# CTRL_MMR0_CFG0 register map
Vendor: Texas Instruments
Registers are 32-bit, read-write, reset 0x0 unless marked. A register's access mark holds for its fields unless they carry their own. Offsets are as the file gives them; [hi:lo] are bit positions; {n}, {i} and the like mark numbered series.

## CTRL_MMR0_CFG0 (part 2 of 2)
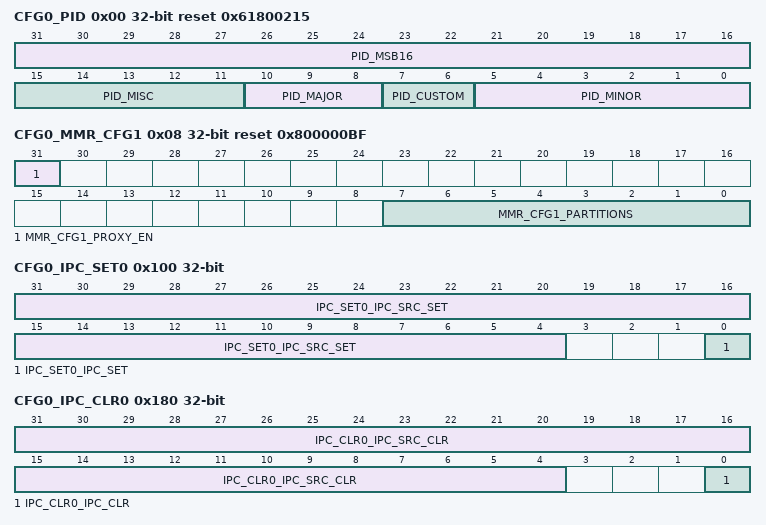
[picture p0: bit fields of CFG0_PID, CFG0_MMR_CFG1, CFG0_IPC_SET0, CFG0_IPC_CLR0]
0x00 CFG0_PID ro reset 0x61800215
  [31:16] PID_MSB16, [15:11] PID_MISC, [10:8] PID_MAJOR, [7:6] PID_CUSTOM, [5:0] PID_MINOR
0x08 CFG0_MMR_CFG1 ro reset 0x800000BF
  [31] MMR_CFG1_PROXY_EN — Proxy addressing activated
  [7:0] MMR_CFG1_PARTITIONS — Indicates present partitions
0x100 CFG0_IPC_SET0 access not given
  [31:4] IPC_SET0_IPC_SRC_SET — Read returns current value Write: 0 - No effect 1 - Sets both corresponding IPC_CLR and the IPC_SET bits (access R/W1TS)
  [0] IPC_SET0_IPC_SET — Read returns 0 Write: 0 - No effect 1 - Sets both corresponding IPC_CLR and the IPC_SET bits (access R/W1TS)
0x180 CFG0_IPC_CLR0 access not given
  [31:4] IPC_CLR0_IPC_SRC_CLR — Read returns current value Write: 0 - No effect 1 - Clears both corresponding IPC_CLR and the IPC_SET bits (access R/W1TC)
  [0] IPC_CLR0_IPC_CLR — Read returns current value Write: 0 - No effect 1 - Clears both corresponding IPC_CLR and the IPC_SET bits (access R/W1TC)
{0x1008+0x4000*i} CFG0_LOCK{i}_KICK0 (i=0..2)
  [31:0] LOCK{i}_KICK0 — - KICK0 component
{0x100C+0x4000*i} CFG0_LOCK{i}_KICK1 (i=0..2)
  [31:0] LOCK{i}_KICK1 — - KICK1 component
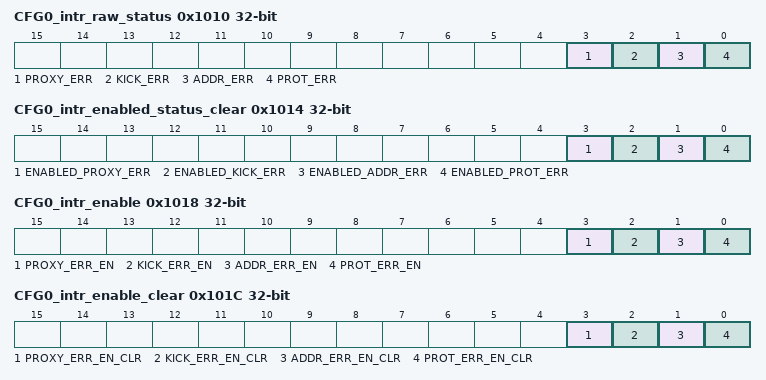
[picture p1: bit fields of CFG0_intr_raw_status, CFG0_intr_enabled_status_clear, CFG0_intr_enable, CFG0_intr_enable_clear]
0x1010 CFG0_intr_raw_status access not given
  [3] PROXY_ERR — Proxy0 access violation error. Raw status is read. Write a 1 to set the status. Writing a 0 has no effect. (access R/W1TS)
  [2] KICK_ERR — Kick access violation error. Raw status is read. Write a 1 to set the status. Writing a 0 has no effect. (access R/W1TS)
  [1] ADDR_ERR — Addressing violation error. Raw status is read. Write a 1 to set the status. Writing a 0 has no effect. (access R/W1TS)
  [0] PROT_ERR — Protection violation error. Raw status is read. Write a 1 to set the status. Writing a 0 has no effect. (access R/W1TS)
0x1014 CFG0_intr_enabled_status_clear access not given
  [3] ENABLED_PROXY_ERR — Proxy0 access violation error. Enabled status is read. Write a 1 to clear the status. Writing a 0 has no effect. (access R/W1TC)
  [2] ENABLED_KICK_ERR — Kick access violation error. Enabled status is read. Write a 1 to clear the status. Writing a 0 has no effect. (access R/W1TC)
  [1] ENABLED_ADDR_ERR — Addressing violation error. Enabled status is read. Write a 1 to clear the status. Writing a 0 has no effect. (access R/W1TC)
  [0] ENABLED_PROT_ERR — Protection violation error. Enabled status is read. Write a 1 to clear the status. Writing a 0 has no effect. (access R/W1TC)
0x1018 CFG0_intr_enable access not given
  [3] PROXY_ERR_EN — Proxy0 access violation error enable. Write a 1 to set the enable. Writing a 0 has no effect. (access R/W1TS)
  [2] KICK_ERR_EN — Kick access violation error enable. Write a 1 to set the enable. Writing a 0 has no effect. (access R/W1TS)
  [1] ADDR_ERR_EN — Addressing violation error enable. Write a 1 to set the enable. Writing a 0 has no effect. (access R/W1TS)
  [0] PROT_ERR_EN — Protection violation error enable. Write a 1 to set the enable. Writing a 0 has no effect. (access R/W1TS)
0x101C CFG0_intr_enable_clear access not given
  [3] PROXY_ERR_EN_CLR — Proxy0 access violation error enable clear. Write a 1 to clear the enable. Writing a 0 has no effect. (access R/W1TC)
  [2] KICK_ERR_EN_CLR — Kick access violation error enable clear. Write a 1 to clear the enable. Writing a 0 has no effect. (access R/W1TC)
  [1] ADDR_ERR_EN_CLR — Addressing violation error enable clear. Write a 1 to clear the enable. Writing a 0 has no effect. (access R/W1TC)
  [0] PROT_ERR_EN_CLR — Protection violation error enable clear. Write a 1 to clear the enable. Writing a 0 has no effect. (access R/W1TC)
0x1020 CFG0_eoi
  [7:0] EOI_VECTOR — EOI vector value. Write this with interrupt distribution value in the chip.
0x1024 CFG0_fault_address ro
  [31:0] FAULT_ADDR — Fault Address.
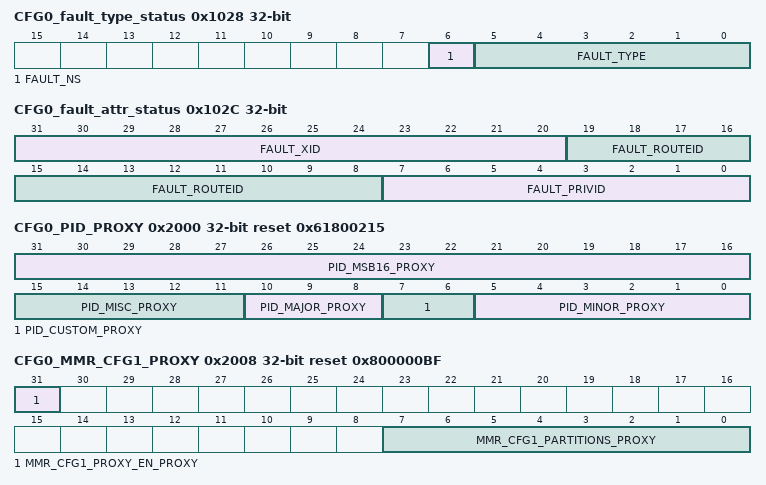
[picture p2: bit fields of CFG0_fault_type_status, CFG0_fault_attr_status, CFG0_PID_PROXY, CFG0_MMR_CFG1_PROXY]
0x1028 CFG0_fault_type_status ro
  [6] FAULT_NS — Non-secure access.
  [5:0] FAULT_TYPE — Fault Type 10_0000 = Supervisor read fault - priv = 1 dir = 1 dtype != 1 01_0000 = Supervisor write fault - priv = 1 dir = 0 00_1000 = Supervisor execute fault - priv = 1 dir = 1 dtype = 1 00_0100 = User read fault - priv = 0 dir = 1 dtype = 1 00_0010 = User write fault - priv = 0 dir = 0 00_0001 = User execute fault - priv = 0 dir = 1 dtype = 1 00_0000 = No fault
0x102C CFG0_fault_attr_status ro
  [31:20] FAULT_XID — XID.
  [19:8] FAULT_ROUTEID — Route ID.
  [7:0] FAULT_PRIVID — Privilege ID.
0x1030 CFG0_fault_clear wo
  [0] FAULT_CLR — Fault clear. Writing a 1 clears the current fault. Writing a 0 has no effect.
{0x1100+4i} CFG0_CLAIMREG_P0_R{i}_READONLY ro (i=0..6)
  [31:0] CLAIMREG_P0_R{i}_READONLY — Claim bits for Partition 0
0x2000 CFG0_PID_PROXY ro reset 0x61800215
  [31:16] PID_MSB16_PROXY, [15:11] PID_MISC_PROXY, [10:8] PID_MAJOR_PROXY, [7:6] PID_CUSTOM_PROXY, [5:0] PID_MINOR_PROXY
0x2008 CFG0_MMR_CFG1_PROXY ro reset 0x800000BF
  [31] MMR_CFG1_PROXY_EN_PROXY — Proxy addressing activated
  [7:0] MMR_CFG1_PARTITIONS_PROXY — Indicates present partitions
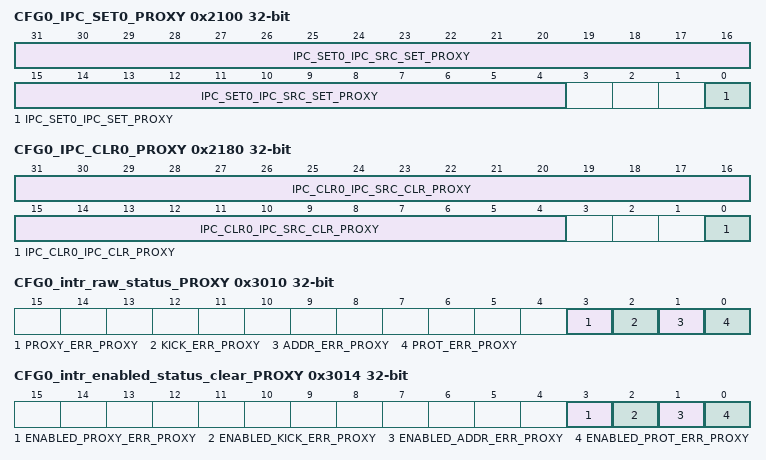
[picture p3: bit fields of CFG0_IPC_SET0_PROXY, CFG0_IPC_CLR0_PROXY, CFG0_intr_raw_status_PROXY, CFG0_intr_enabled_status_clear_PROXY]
0x2100 CFG0_IPC_SET0_PROXY access not given
  [31:4] IPC_SET0_IPC_SRC_SET_PROXY — Read returns current value Write: 0 - No effect 1 - Sets both corresponding IPC_CLR and the IPC_SET bits (access R/W1TS)
  [0] IPC_SET0_IPC_SET_PROXY — Read returns 0 Write: 0 - No effect 1 - Sets both corresponding IPC_CLR and the IPC_SET bits (access R/W1TS)
0x2180 CFG0_IPC_CLR0_PROXY access not given
  [31:4] IPC_CLR0_IPC_SRC_CLR_PROXY — Read returns current value Write: 0 - No effect 1 - Clears both corresponding IPC_CLR and the IPC_SET bits (access R/W1TC)
  [0] IPC_CLR0_IPC_CLR_PROXY — Read returns current value Write: 0 - No effect 1 - Clears both corresponding IPC_CLR and the IPC_SET bits (access R/W1TC)
{0x3008+0x4000*i} CFG0_LOCK{i}_KICK0_PROXY (i=0..2)
  [31:0] LOCK{i}_KICK0_PROXY — - KICK0 component
{0x300C+0x4000*i} CFG0_LOCK{i}_KICK1_PROXY (i=0..2)
  [31:0] LOCK{i}_KICK1_PROXY — - KICK1 component
0x3010 CFG0_intr_raw_status_PROXY access not given
  [3] PROXY_ERR_PROXY — Proxy0 access violation error. Raw status is read. Write a 1 to set the status. Writing a 0 has no effect. (access R/W1TS)
  [2] KICK_ERR_PROXY — Kick access violation error. Raw status is read. Write a 1 to set the status. Writing a 0 has no effect. (access R/W1TS)
  [1] ADDR_ERR_PROXY — Addressing violation error. Raw status is read. Write a 1 to set the status. Writing a 0 has no effect. (access R/W1TS)
  [0] PROT_ERR_PROXY — Protection violation error. Raw status is read. Write a 1 to set the status. Writing a 0 has no effect. (access R/W1TS)
0x3014 CFG0_intr_enabled_status_clear_PROXY access not given
  [3] ENABLED_PROXY_ERR_PROXY — Proxy0 access violation error. Enabled status is read. Write a 1 to clear the status. Writing a 0 has no effect. (access R/W1TC)
  [2] ENABLED_KICK_ERR_PROXY — Kick access violation error. Enabled status is read. Write a 1 to clear the status. Writing a 0 has no effect. (access R/W1TC)
  [1] ENABLED_ADDR_ERR_PROXY — Addressing violation error. Enabled status is read. Write a 1 to clear the status. Writing a 0 has no effect. (access R/W1TC)
  [0] ENABLED_PROT_ERR_PROXY — Protection violation error. Enabled status is read. Write a 1 to clear the status. Writing a 0 has no effect. (access R/W1TC)
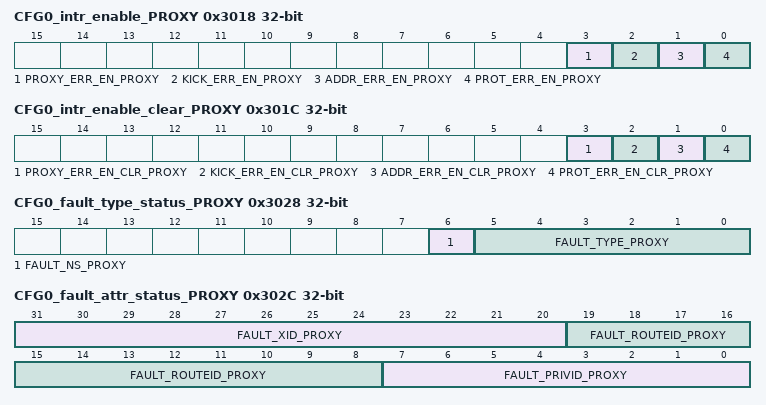
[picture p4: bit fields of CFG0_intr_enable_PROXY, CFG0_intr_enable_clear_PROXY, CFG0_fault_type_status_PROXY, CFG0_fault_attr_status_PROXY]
0x3018 CFG0_intr_enable_PROXY access not given
  [3] PROXY_ERR_EN_PROXY — Proxy0 access violation error enable. Write a 1 to set the enable. Writing a 0 has no effect. (access R/W1TS)
  [2] KICK_ERR_EN_PROXY — Kick access violation error enable. Write a 1 to set the enable. Writing a 0 has no effect. (access R/W1TS)
  [1] ADDR_ERR_EN_PROXY — Addressing violation error enable. Write a 1 to set the enable. Writing a 0 has no effect. (access R/W1TS)
  [0] PROT_ERR_EN_PROXY — Protection violation error enable. Write a 1 to set the enable. Writing a 0 has no effect. (access R/W1TS)
0x301C CFG0_intr_enable_clear_PROXY access not given
  [3] PROXY_ERR_EN_CLR_PROXY — Proxy0 access violation error enable clear. Write a 1 to clear the enable. Writing a 0 has no effect. (access R/W1TC)
  [2] KICK_ERR_EN_CLR_PROXY — Kick access violation error enable clear. Write a 1 to clear the enable. Writing a 0 has no effect. (access R/W1TC)
  [1] ADDR_ERR_EN_CLR_PROXY — Addressing violation error enable clear. Write a 1 to clear the enable. Writing a 0 has no effect. (access R/W1TC)
  [0] PROT_ERR_EN_CLR_PROXY — Protection violation error enable clear. Write a 1 to clear the enable. Writing a 0 has no effect. (access R/W1TC)
0x3020 CFG0_eoi_PROXY
  [7:0] EOI_VECTOR_PROXY — EOI vector value. Write this with interrupt distribution value in the chip.
0x3024 CFG0_fault_address_PROXY ro
  [31:0] FAULT_ADDR_PROXY — Fault Address.
0x3028 CFG0_fault_type_status_PROXY ro
  [6] FAULT_NS_PROXY — Non-secure access.
  [5:0] FAULT_TYPE_PROXY — Fault Type 10_0000 = Supervisor read fault - priv = 1 dir = 1 dtype != 1 01_0000 = Supervisor write fault - priv = 1 dir = 0 00_1000 = Supervisor execute fault - priv = 1 dir = 1 dtype = 1 00_0100 = User read fault - priv = 0 dir = 1 dtype = 1 00_0010 = User write fault - priv = 0 dir = 0 00_0001 = User execute fault - priv = 0 dir = 1 dtype = 1 00_0000 = No fault
0x302C CFG0_fault_attr_status_PROXY ro
  [31:20] FAULT_XID_PROXY — XID.
  [19:8] FAULT_ROUTEID_PROXY — Route ID.
  [7:0] FAULT_PRIVID_PROXY — Privilege ID.
0x3030 CFG0_fault_clear_PROXY wo
  [0] FAULT_CLR_PROXY — Fault clear. Writing a 1 clears the current fault. Writing a 0 has no effect.
{0x3100+4i} CFG0_CLAIMREG_P0_R{i} (i=0..6)
  [31:0] CLAIMREG_P0_R{i} — Claim bits for Partition 0
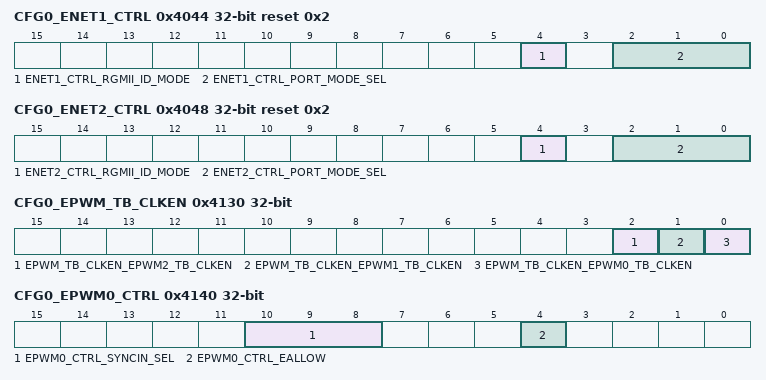
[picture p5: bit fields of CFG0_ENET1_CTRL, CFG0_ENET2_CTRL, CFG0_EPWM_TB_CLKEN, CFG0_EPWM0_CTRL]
0x4044 CFG0_ENET1_CTRL reset 0x2
  [4] ENET1_CTRL_RGMII_ID_MODE — Port1 RGMII internal transmit delay selection 0 - Internal transmit delay 1 - No intenal transmit delay
  [2:0] ENET1_CTRL_PORT_MODE_SEL — Selects Ethernet switch Port1 interface Field values (others are reserved): 3'b000 - GMII/MII (not supported) 3'b001 - RMII 3'b010 - RGMII 3'b011 - SGMII (not supported) 3'b100 - QSGMII (not supported) 3'b101 - XFI (not supported) 3'b110 - QSGMII_SUB (not supported) 3'b111 - Reserved
0x4048 CFG0_ENET2_CTRL reset 0x2
  [4] ENET2_CTRL_RGMII_ID_MODE — Port2 RGMII internal transmit delay selection 0 - Internal transmit delay 1 - No intenal transmit delay
  [2:0] ENET2_CTRL_PORT_MODE_SEL — Selects Ethernet switch Port2 interface Field values (others are reserved): 3'b000 - GMII/MII (not supported) 3'b001 - RMII 3'b010 - RGMII 3'b011 - SGMII (not supported) 3'b100 - QSGMII (not supported) 3'b101 - XFI (not supported) 3'b110 - QSGMII_SUB (not supported) 3'b111 - Reserved
0x4130 CFG0_EPWM_TB_CLKEN
  [2] EPWM_TB_CLKEN_EPWM2_TB_CLKEN — Activates Timebase Clock of EPWM2 When Set
  [1] EPWM_TB_CLKEN_EPWM1_TB_CLKEN — Activates Timebase Clock of EPWM1 When Set
  [0] EPWM_TB_CLKEN_EPWM0_TB_CLKEN — Activates Timebase Clock of EPWM0 When Set
0x4140 CFG0_EPWM0_CTRL
  [10:8] EPWM0_CTRL_SYNCIN_SEL — Selects the source of the EPWM0 synchronization input Field values (others are reserved): 3'b000 - EPWM0_SYNCIN Pin 3'b001 - None 3'b010 - Time Sync Router 19 3'b011 - Compare Event Router 32 undefined - undefined 3'b100 - None 3'b101 - None 3'b110 - None 3'b111 - None
  [4] EPWM0_CTRL_EALLOW — Activate write access to EPWM tripzone registers 0 - Deactivated 1 - Activated
0x4144 CFG0_EPWM1_CTRL
  [4] EPWM1_CTRL_EALLOW — Activate write access to EPWM tripzone registers 0 - Deactivated 1 - Activated
0x4148 CFG0_EPWM2_CTRL
  [4] EPWM2_CTRL_EALLOW — Activate write access to EPWM tripzone registers 0 - Deactivated 1 - Activated
{0x4180+4i} CFG0_EQEP{i}_CTRL (i=0..2)
  [4:0] EQEP{i}_CTRL_SOCA_SEL — Selects the source of SOCA input for EQEP{i} Field values (others are reserved): undefined - undefined undefined - undefined 5'b00010 - EPWM SOCA_OUT 5'b00011 - EPWM SOCB_OUT 5'b00100 - MCU_TIMER0 PWM 5'b00101 - MCU_TIMER1 PWM 5'b00110 - MCU_TIMER2 PWM 5'b00111 - MCU_TIMER3 PWM 5'b01000 - TIMER0 PWM 5'b01001 - TIMER1 PWM 5'b01010 - TIMER2 PWM 5'b01011 - TIMER3 PWM 5'b01100 - TIMER4 PWM 5'b01101 - TIMER5 PWM 5'b01110 - TIMER6 PWM 5'b01111 - TIMER7 PWM 5'b10000 - WKUP TIMER0 PWM 5'b10001 - WKUP TIMER1 PWM
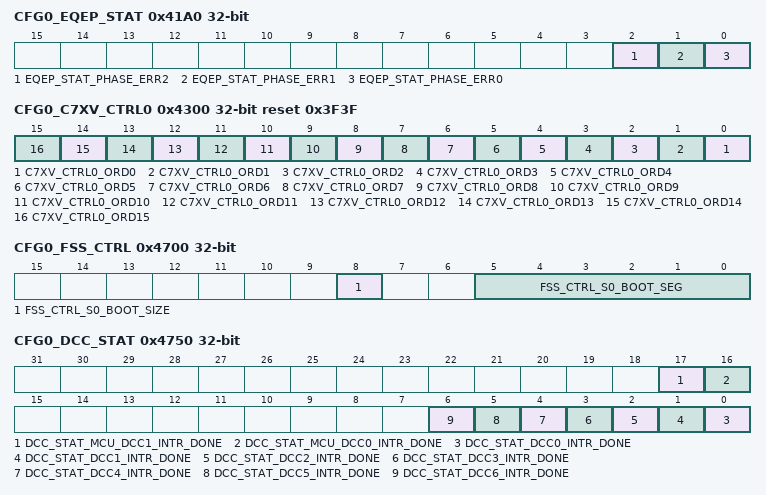
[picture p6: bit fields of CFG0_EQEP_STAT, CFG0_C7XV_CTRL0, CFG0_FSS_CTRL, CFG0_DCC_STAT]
0x41A0 CFG0_EQEP_STAT ro
  [2] EQEP_STAT_PHASE_ERR2 — EQEP2 Phase error status 0 - No error 1 - Phase error occurred
  [1] EQEP_STAT_PHASE_ERR1 — EQEP1 Phase error status 0 - No error 1 - Phase error occurred
  [0] EQEP_STAT_PHASE_ERR0 — EQEP0 Phase error status 0 - No error 1 - Phase error occurred
0x4204 CFG0_TIMER1_CTRL
  [8] TIMER1_CTRL_CASCADE_EN — Activates cascading of TIMER1 to TIMER0
0x420C CFG0_TIMER3_CTRL
  [8] TIMER3_CTRL_CASCADE_EN — Activates cascading of TIMER3 to TIMER2
0x4214 CFG0_TIMER5_CTRL
  [8] TIMER5_CTRL_CASCADE_EN — Activates cascading of TIMER5 to TIMER4
0x421C CFG0_TIMER7_CTRL
  [8] TIMER7_CTRL_CASCADE_EN — Activates cascading of TIMER7 to TIMER6
0x4300 CFG0_C7XV_CTRL0 reset 0x3F3F
  [n] C7XV_CTRL0_ORD{n} (n=0..15) — Ordering Rule for Order ID {n} Field values (others are reserved): 1'b1 - RELAXED_R_TO_W 1'b0 - RELAXED_READ
{0x44C0+4i} CFG0_EMMC{i}_STAT ro (i=0..2)
  [0] EMMC{i}_STAT_SIG1P8_EN — Status of 1.8V Signal Activate from EMMC{i} Module
0x4700 CFG0_FSS_CTRL
  [8] FSS_CTRL_S0_BOOT_SIZE — Selects the size of the boot block to be used for the S0 (OSPI0) flash interface 0 - S0 boot size is 64 MB 1 - S0 boot size is 128 MB
  [5:0] FSS_CTRL_S0_BOOT_SEG — Selects the boot block to be used for the S0 (OSPI0) flash interface. If the s0_boot_size is 128 MB then only bits [4:0] of this field are used. Care must be taken to account for the address translation as to not fall off or wrap the address of the flash. (e.g. if both ECC and authentication are activated for 64 MB boot, the highest valid block number is is 49, as sector 50 is only .2M Bytes in size.) 6'h00 - Use block 0 6'h01 - Use block 1 : 6'h3F - Use block 63
0x4750 CFG0_DCC_STAT ro
  [17] DCC_STAT_MCU_DCC1_INTR_DONE — MCU_DCC1 Done Interrupt Status 0 = No Interrupt Pending 1 = Interrupt Pending
  [16] DCC_STAT_MCU_DCC0_INTR_DONE — MCU_DCC0 Done Interrupt Status 0 = No Interrupt Pending 1 = Interrupt Pending
  [n] DCC_STAT_DCC{n}_INTR_DONE (n=0..6) — DCC{n} Done Interrupt Status 0 = No Interrupt Pending 1 = Interrupt Pending
{0x5100+4i} CFG0_CLAIMREG_P1_R{i}_READONLY ro (i=0..14)
  [31:0] CLAIMREG_P1_R{i}_READONLY — Claim bits for Partition 1
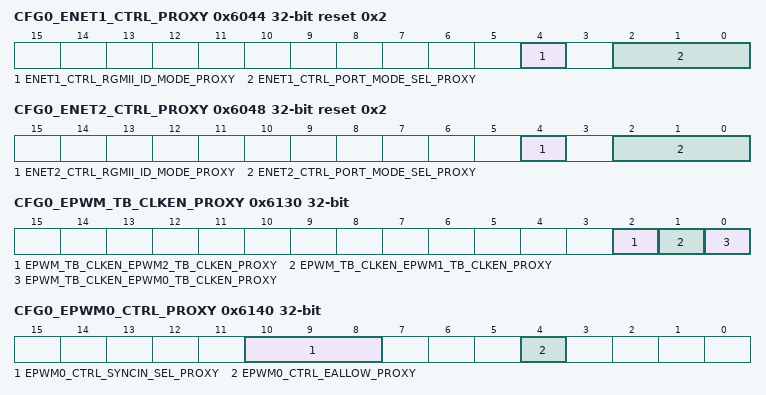
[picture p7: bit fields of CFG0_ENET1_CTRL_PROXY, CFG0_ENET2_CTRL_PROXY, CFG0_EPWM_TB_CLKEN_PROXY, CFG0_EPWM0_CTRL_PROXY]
0x6044 CFG0_ENET1_CTRL_PROXY reset 0x2
  [4] ENET1_CTRL_RGMII_ID_MODE_PROXY — Port1 RGMII internal transmit delay selection 0 - Internal transmit delay 1 - No intenal transmit delay
  [2:0] ENET1_CTRL_PORT_MODE_SEL_PROXY — Selects Ethernet switch Port1 interface Field values (others are reserved): 3'b000 - GMII/MII (not supported) 3'b001 - RMII 3'b010 - RGMII 3'b011 - SGMII (not supported) 3'b100 - QSGMII (not supported) 3'b101 - XFI (not supported) 3'b110 - QSGMII_SUB (not supported) 3'b111 - Reserved
0x6048 CFG0_ENET2_CTRL_PROXY reset 0x2
  [4] ENET2_CTRL_RGMII_ID_MODE_PROXY — Port2 RGMII internal transmit delay selection 0 - Internal transmit delay 1 - No intenal transmit delay
  [2:0] ENET2_CTRL_PORT_MODE_SEL_PROXY — Selects Ethernet switch Port2 interface Field values (others are reserved): 3'b000 - GMII/MII (not supported) 3'b001 - RMII 3'b010 - RGMII 3'b011 - SGMII (not supported) 3'b100 - QSGMII (not supported) 3'b101 - XFI (not supported) 3'b110 - QSGMII_SUB (not supported) 3'b111 - Reserved
0x6130 CFG0_EPWM_TB_CLKEN_PROXY
  [2] EPWM_TB_CLKEN_EPWM2_TB_CLKEN_PROXY — Activates Timebase Clock of EPWM2 When Set
  [1] EPWM_TB_CLKEN_EPWM1_TB_CLKEN_PROXY — Activates Timebase Clock of EPWM1 When Set
  [0] EPWM_TB_CLKEN_EPWM0_TB_CLKEN_PROXY — Activates Timebase Clock of EPWM0 When Set
0x6140 CFG0_EPWM0_CTRL_PROXY
  [10:8] EPWM0_CTRL_SYNCIN_SEL_PROXY — Selects the source of the EPWM0 synchronization input Field values (others are reserved): 3'b000 - EPWM0_SYNCIN Pin 3'b001 - None 3'b010 - Time Sync Router 19 3'b011 - Compare Event Router 32 undefined - undefined 3'b100 - None 3'b101 - None 3'b110 - None 3'b111 - None
  [4] EPWM0_CTRL_EALLOW_PROXY — Activate write access to EPWM tripzone registers 0 - Deactivated 1 - Activated
0x6144 CFG0_EPWM1_CTRL_PROXY
  [4] EPWM1_CTRL_EALLOW_PROXY — Activate write access to EPWM tripzone registers 0 - Deactivated 1 - Activated
0x6148 CFG0_EPWM2_CTRL_PROXY
  [4] EPWM2_CTRL_EALLOW_PROXY — Activate write access to EPWM tripzone registers 0 - Deactivated 1 - Activated
{0x6180+4i} CFG0_EQEP{i}_CTRL_PROXY (i=0..2)
  [4:0] EQEP{i}_CTRL_SOCA_SEL_PROXY — Selects the source of SOCA input for EQEP{i} Field values (others are reserved): undefined - undefined undefined - undefined 5'b00010 - EPWM SOCA_OUT 5'b00011 - EPWM SOCB_OUT 5'b00100 - MCU_TIMER0 PWM 5'b00101 - MCU_TIMER1 PWM 5'b00110 - MCU_TIMER2 PWM 5'b00111 - MCU_TIMER3 PWM 5'b01000 - TIMER0 PWM 5'b01001 - TIMER1 PWM 5'b01010 - TIMER2 PWM 5'b01011 - TIMER3 PWM 5'b01100 - TIMER4 PWM 5'b01101 - TIMER5 PWM 5'b01110 - TIMER6 PWM 5'b01111 - TIMER7 PWM 5'b10000 - WKUP TIMER0 PWM 5'b10001 - WKUP TIMER1 PWM
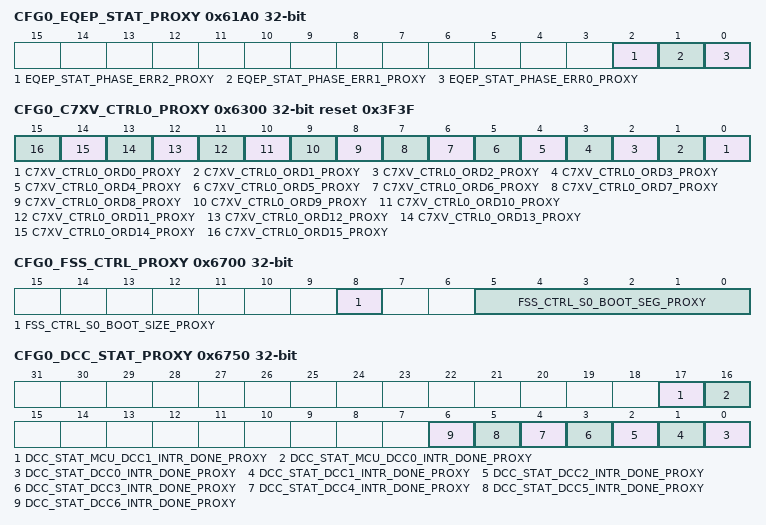
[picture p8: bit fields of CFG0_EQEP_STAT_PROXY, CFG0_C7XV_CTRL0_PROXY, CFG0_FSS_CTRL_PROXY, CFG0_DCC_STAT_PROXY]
0x61A0 CFG0_EQEP_STAT_PROXY ro
  [2] EQEP_STAT_PHASE_ERR2_PROXY — EQEP2 Phase error status 0 - No error 1 - Phase error occurred
  [1] EQEP_STAT_PHASE_ERR1_PROXY — EQEP1 Phase error status 0 - No error 1 - Phase error occurred
  [0] EQEP_STAT_PHASE_ERR0_PROXY — EQEP0 Phase error status 0 - No error 1 - Phase error occurred
0x6204 CFG0_TIMER1_CTRL_PROXY
  [8] TIMER1_CTRL_CASCADE_EN_PROXY — Activates cascading of TIMER1 to TIMER0
0x620C CFG0_TIMER3_CTRL_PROXY
  [8] TIMER3_CTRL_CASCADE_EN_PROXY — Activates cascading of TIMER3 to TIMER2
0x6214 CFG0_TIMER5_CTRL_PROXY
  [8] TIMER5_CTRL_CASCADE_EN_PROXY — Activates cascading of TIMER5 to TIMER4
0x621C CFG0_TIMER7_CTRL_PROXY
  [8] TIMER7_CTRL_CASCADE_EN_PROXY — Activates cascading of TIMER7 to TIMER6
0x6300 CFG0_C7XV_CTRL0_PROXY reset 0x3F3F
  [n] C7XV_CTRL0_ORD{n}_PROXY (n=0..15) — Ordering Rule for Order ID {n} Field values (others are reserved): 1'b1 - RELAXED_R_TO_W 1'b0 - RELAXED_READ
{0x64C0+4i} CFG0_EMMC{i}_STAT_PROXY ro (i=0..2)
  [0] EMMC{i}_STAT_SIG1P8_EN_PROXY — Status of 1.8V Signal Activate from EMMC{i} Module
0x6700 CFG0_FSS_CTRL_PROXY
  [8] FSS_CTRL_S0_BOOT_SIZE_PROXY — Selects the size of the boot block to be used for the S0 (OSPI0) flash interface 0 - S0 boot size is 64 MB 1 - S0 boot size is 128 MB
  [5:0] FSS_CTRL_S0_BOOT_SEG_PROXY — Selects the boot block to be used for the S0 (OSPI0) flash interface. If the s0_boot_size is 128 MB then only bits [4:0] of this field are used. Care must be taken to account for the address translation as to not fall off or wrap the address of the flash. (e.g. if both ECC and authentication are activated for 64 MB boot, the highest valid block number is is 49, as sector 50 is only .2M Bytes in size.) 6'h00 - Use block 0 6'h01 - Use block 1 : 6'h3F - Use block 63
0x6750 CFG0_DCC_STAT_PROXY ro
  [17] DCC_STAT_MCU_DCC1_INTR_DONE_PROXY — MCU_DCC1 Done Interrupt Status 0 = No Interrupt Pending 1 = Interrupt Pending
  [16] DCC_STAT_MCU_DCC0_INTR_DONE_PROXY — MCU_DCC0 Done Interrupt Status 0 = No Interrupt Pending 1 = Interrupt Pending
  [n] DCC_STAT_DCC{n}_INTR_DONE_PROXY (n=0..6) — DCC{n} Done Interrupt Status 0 = No Interrupt Pending 1 = Interrupt Pending
{0x7100+4i} CFG0_CLAIMREG_P1_R{i} (i=0..14)
  [31:0] CLAIMREG_P1_R{i} — Claim bits for Partition 1
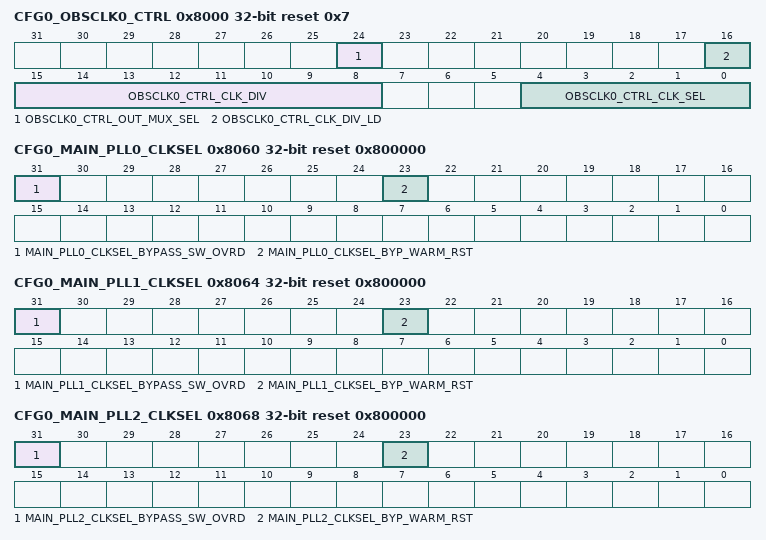
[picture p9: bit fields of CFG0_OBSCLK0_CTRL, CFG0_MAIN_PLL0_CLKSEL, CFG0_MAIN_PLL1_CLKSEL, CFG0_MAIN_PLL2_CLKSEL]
0x8000 CFG0_OBSCLK0_CTRL reset 0x7
  [24] OBSCLK0_CTRL_OUT_MUX_SEL — OBSCLK pin output mux selection. Note, HFOSC0_CLK is a direct output from the HFOSC0, distinct from HFOSC0_CLKOUT. Note, when HFOSC0_CLK is selected (1'b1) the MCU_OBSCLK_CTRL_clk_sel field must be programmed to 5'b11111. 1'b0 - The output of the MCU_OBSCLK output divider is output on the pin 1'b1 - HFOSC0_CLK is output on the pin
  [16] OBSCLK0_CTRL_CLK_DIV_LD — Load the output divider value Writing 1 to this bit will generate a load pulse to load the OBSCLK0 divider value. This bit can be cleared but must not be set in the same write cycle in which the clk_div value is changed.
  [15:8] OBSCLK0_CTRL_CLK_DIV — OBSCLK0 output divider Divides the selected clock by clkdiv+1 for output to the OBSCLK0 pins. Supports divide by 1 to 256 (default to 1). To load the new divider value the clk_div_ld bit must be cleared and then set to 1.
  [4:0] OBSCLK0_CTRL_CLK_SEL — OBSCLK0 clock source selection. Selects the source of the clock to be divided by the OBSCLK0 divider and output on the OBSCLK0 pin. Field values (others are reserved): 5'b00000 - MAIN_PLL0_HSDIV0_CLKOUT 5'b00001 - MAIN_PLL1_HSDIV0_CLKOUT 5'b00010 - MAIN_PLL2_HSDIV0_CLKOUT 5'b00011 - MAIN_PLL8_HSDIV0_CLKOUT_DIV4 5'b00100 - MAIN_PLL12_HSDIV0_CLKOUT_DIV4 5'b00101 - CLK_12M_RC 5'b00110 - HFOSC0_CLKOUT_32K 5'b00111 - PLLCTRL_OBSCLK 5'b01000 - HFOSC0_CLKOUT 5'b01001 - CLK_32K 5'b01010 - cpsw2g_cpts_genf0 5'b01011 - cpsw2g_cpts_genf1 5'b01100 - MCU_PLL0_HSDIV0_CLKOUT 5'b01101 - MAIN_PLL15_HSDIV0_CLKOUT undefined - undefined 5'b01110 - reserved 5'b01111 - MAIN_PLL17_HSDIV0_CLKOUT 5'b10000 - MAIN_SYSCLK0 5'b10001 - DEVICE_CLKOUT_32K 5'b10010 - MAIN_PLL5_HSDIV0_CLKOUT 5'b10011 - MAIN_PLL7_HSDIV0_CLKOUT_DIV4
0x8010 CFG0_CLKOUT_CTRL
  [0] CLKOUT_CTRL_CLK_SEL — Selects CLKOUT clock source Field values (others are reserved): 1'b0 - MAIN_PLL2_HSDIV1_CLKOUT / 5 1'b1 - MAIN_PLL2_HSDIV1_CLKOUT / 10
0x8060 CFG0_MAIN_PLL0_CLKSEL reset 0x800000
  [31] MAIN_PLL0_CLKSEL_BYPASS_SW_OVRD — PLL Bypass warm reset software override When set, activates software control of exit from bypass mode on a main_reset_z for MAIN PLL0. This bit must not be set until after the corresponding byp_warm_rst bit has been cleared or the PLL will immediately enter bypass mode.
  [23] MAIN_PLL0_CLKSEL_BYP_WARM_RST — PLL bypass mode after warm reset. This bit is only valid when bypass_sw_ovrd is set to 1'b1 to activate bypass software override. This bit is set (1'b0) when a MAIN warm reset occurs to keep MAIN PLL0 from being bypassed, supporting reset isolation of the CPSW. 1'b0 = Exit bypass mode (based on MAIN PLL0_CTRL_bypass_en bit value) 1'b1 = Maintain bypass mode.
0x8064 CFG0_MAIN_PLL1_CLKSEL reset 0x800000
  [31] MAIN_PLL1_CLKSEL_BYPASS_SW_OVRD — PLL Bypass warm reset software override This bit has no effect on PLL operation as MAIN PLL1 is reset isolated and exit from bypass mode (in the case of a Thermal reset) is always hardware controlled.
  [23] MAIN_PLL1_CLKSEL_BYP_WARM_RST — PLL bypass mode after warm reset. This bit is cleared to 1'b0 when a MAIN warm reset occurs which will cause MAIN PLL1 to exit bypass mode after reset exit. Setting this bit will have no effect on PLL behaviot. Because MAIN PLL1 is warm reset insensitive, bypass mode will only be entered (and exited) in the case of a Thermal reset event.
0x8068 CFG0_MAIN_PLL2_CLKSEL reset 0x800000
  [31] MAIN_PLL2_CLKSEL_BYPASS_SW_OVRD — PLL Bypass warm reset software override This bit has no effect on PLL operation as MAIN PLL2 is reset isolated and exit from bypass mode (in the case of a Thermal reset) is always hardware controlled.
  [23] MAIN_PLL2_CLKSEL_BYP_WARM_RST — PLL bypass mode after warm reset. This bit is cleared to 1'b0 when a MAIN warm reset occurs which will cause MAIN PLL2 to exit bypass mode after reset exit. Setting this bit will have no effect on PLL behaviot. Because MAIN PLL2 is warm reset insensitive, bypass mode will only be entered (and exited) in the case of a Thermal reset event.
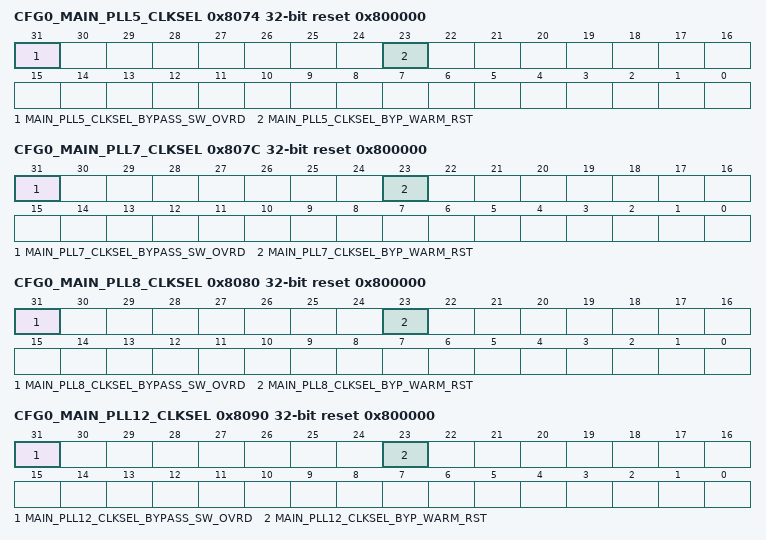
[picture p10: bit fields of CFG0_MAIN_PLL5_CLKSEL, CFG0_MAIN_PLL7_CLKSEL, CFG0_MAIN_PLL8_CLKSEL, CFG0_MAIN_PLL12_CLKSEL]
0x8074 CFG0_MAIN_PLL5_CLKSEL reset 0x800000
  [31] MAIN_PLL5_CLKSEL_BYPASS_SW_OVRD — PLL Bypass warm reset software override When set, activates software control of exit from bypass mode on a main_reset_z for MAIN PLL5. This bit must not be set until after the corresponding byp_warm_rst bit has been cleared or the PLL will immediately enter bypass mode.
  [23] MAIN_PLL5_CLKSEL_BYP_WARM_RST — PLL bypass mode after warm reset. This bit is only valid when bypass_sw_ovrd is set to 1'b1 to activate bypass software override. This bit is set (1'b1) when a MAIN warm reset occurs and will keep MAIN PLL5 in bypass mode after reset exit until cleared by software. 1'b0 = Exit bypass mode (based on MAIN PLL5_CTRL_bypass_en bit value) 1'b1 = Maintain bypass mode.
0x807C CFG0_MAIN_PLL7_CLKSEL reset 0x800000
  [31] MAIN_PLL7_CLKSEL_BYPASS_SW_OVRD — PLL Bypass warm reset software override When set, activates software control of exit from bypass mode on a main_reset_z for MAIN PLL7. This bit must not be set until after the corresponding byp_warm_rst bit has been cleared or the PLL will immediately enter bypass mode.
  [23] MAIN_PLL7_CLKSEL_BYP_WARM_RST — PLL bypass mode after warm reset. This bit is only valid when bypass_sw_ovrd is set to 1'b1 to activate bypass software override. This bit is set (1'b1) when a MAIN warm reset occurs and will keep MAIN PLL7 in bypass mode after reset exit until cleared by software. 1'b0 = Exit bypass mode (based on MAIN PLL7_CTRL_bypass_en bit value) 1'b1 = Maintain bypass mode.
0x8080 CFG0_MAIN_PLL8_CLKSEL reset 0x800000
  [31] MAIN_PLL8_CLKSEL_BYPASS_SW_OVRD — PLL Bypass warm reset software override When set, activates software control of exit from bypass mode on a main_reset_z for MAIN PLL8. This bit must not be set until after the corresponding byp_warm_rst bit has been cleared or the PLL will immediately enter bypass mode.
  [23] MAIN_PLL8_CLKSEL_BYP_WARM_RST — PLL bypass mode after warm reset. This bit is only valid when bypass_sw_ovrd is set to 1'b1 to activate bypass software override. This bit is set (1'b1) when a MAIN warm reset occurs and will keep MAIN PLL8 in bypass mode after reset exit until cleared by software. 1'b0 = Exit bypass mode (based on MAIN PLL8_CTRL_bypass_en bit value) 1'b1 = Maintain bypass mode.
0x8090 CFG0_MAIN_PLL12_CLKSEL reset 0x800000
  [31] MAIN_PLL12_CLKSEL_BYPASS_SW_OVRD — PLL Bypass warm reset software override When set, activates software control of exit from bypass mode on a main_reset_z for MAIN PLL12. This bit must not be set until after the corresponding byp_warm_rst bit has been cleared or the PLL will immediately enter bypass mode.
  [23] MAIN_PLL12_CLKSEL_BYP_WARM_RST — PLL bypass mode after warm reset. This bit is only valid when bypass_sw_ovrd is set to 1'b1 to activate bypass software override. This bit is set (1'b1) when a MAIN warm reset occurs and will keep MAIN PLL12 in bypass mode after reset exit until cleared by software. 1'b0 = Exit bypass mode (based on MAIN PLL12_CTRL_bypass_en bit value) 1'b1 = Maintain bypass mode.
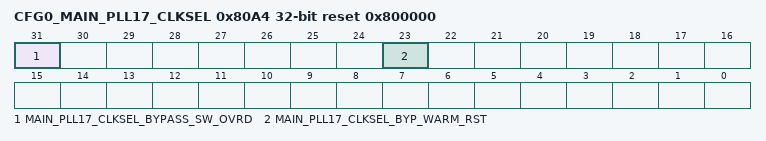
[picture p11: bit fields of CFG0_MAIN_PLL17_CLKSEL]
0x80A4 CFG0_MAIN_PLL17_CLKSEL reset 0x800000
  [31] MAIN_PLL17_CLKSEL_BYPASS_SW_OVRD — PLL Bypass warm reset software override This bit has no effect on PLL operation as MAIN PLL17 is reset isolated and exit from bypass mode (in the case of a Thermal reset) is always hardware controlled.
  [23] MAIN_PLL17_CLKSEL_BYP_WARM_RST — PLL bypass mode after warm reset. This bit is cleared to 1'b0 when a MAIN warm reset occurs which will cause MAIN PLL17 to exit bypass mode after reset exit. Setting this bit will have no effect on PLL behaviot. Because MAIN PLL17 is warm reset insensitive, bypass mode will only be entered (and exited) in the case of a Thermal reset event.
